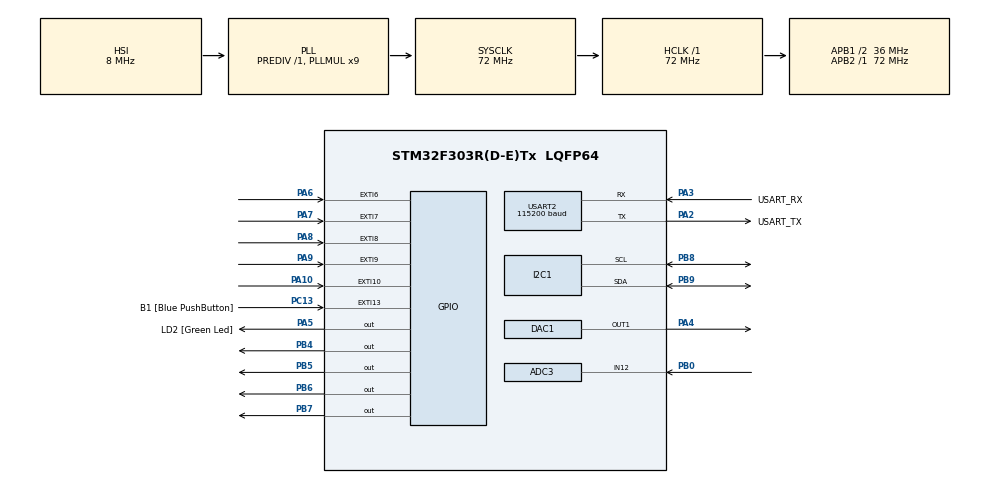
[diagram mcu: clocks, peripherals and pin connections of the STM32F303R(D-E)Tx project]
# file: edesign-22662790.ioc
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ADC1.Channel-2\#ChannelRegularConversion=ADC_CHANNEL_TEMPSENSOR
ADC1.NbrOfConversionFlag=1
ADC1.Offset-2\#ChannelRegularConversion=0
ADC1.OffsetNumber-2\#ChannelRegularConversion=ADC_OFFSET_NONE
ADC1.Rank-2\#ChannelRegularConversion=1
ADC1.SamplingTime-2\#ChannelRegularConversion=ADC_SAMPLETIME_1CYCLE_5
ADC1.master=1
ADC3.Channel-0\#ChannelRegularConversion=ADC_CHANNEL_12
ADC3.ContinuousConvMode=ENABLE
ADC3.DMAContinuousRequests=DISABLE
ADC3.NbrOfConversionFlag=1
ADC3.Offset-0\#ChannelRegularConversion=0
ADC3.OffsetNumber-0\#ChannelRegularConversion=ADC_OFFSET_NONE
ADC3.Rank-0\#ChannelRegularConversion=1
ADC3.SamplingTime-0\#ChannelRegularConversion=ADC_SAMPLETIME_2CYCLES_5
ADC3.master=1
Mcu.Family=STM32F3
Mcu.Name=STM32F303R(D-E)Tx
Mcu.Package=LQFP64
NVIC.ADC3_IRQn=true\:0\:0\:false\:false\:true\:true\:true
NVIC.EXTI15_10_IRQn=true\:0\:0\:false\:false\:true\:true\:true
NVIC.EXTI9_5_IRQn=true\:0\:0\:false\:false\:true\:true\:true
NVIC.PriorityGroup=NVIC_PRIORITYGROUP_0
NVIC.USART2_IRQn=true\:0\:0\:false\:false\:true\:true\:true
PA10.GPIO_ModeDefaultEXTI=GPIO_MODE_IT_RISING_FALLING
PA10.GPIO_PuPd=GPIO_PULLUP
PA10.Signal=GPXTI10
PA13.GPIO_Label=TMS
PA13.Mode=Serial_Wire
PA13.Signal=SYS_JTMS-SWDIO
PA14.GPIO_Label=TCK
PA14.Mode=Serial_Wire
PA14.Signal=SYS_JTCK-SWCLK
PA2.GPIO_Label=USART_TX
PA2.GPIO_Mode=GPIO_MODE_AF_PP
PA2.GPIO_PuPd=GPIO_NOPULL
PA2.GPIO_Speed=GPIO_SPEED_FREQ_LOW
PA2.Mode=Asynchronous
PA2.Signal=USART2_TX
PA3.GPIO_Label=USART_RX
PA3.GPIO_Mode=GPIO_MODE_AF_PP
PA3.GPIO_PuPd=GPIO_NOPULL
PA3.GPIO_Speed=GPIO_SPEED_FREQ_LOW
PA3.Mode=Asynchronous
PA3.Signal=USART2_RX
PA4.Signal=COMP_DAC11_group
PA5.GPIO_Label=LD2 [Green Led]
PA5.GPIO_Mode=GPIO_MODE_OUTPUT_PP
PA5.GPIO_PuPd=GPIO_NOPULL
PA5.GPIO_Speed=GPIO_SPEED_FREQ_LOW
PA5.Signal=GPIO_Output
PA6.GPIO_ModeDefaultEXTI=GPIO_MODE_IT_RISING_FALLING
PA6.GPIO_PuPd=GPIO_PULLUP
PA6.Signal=GPXTI6
PA7.GPIO_ModeDefaultEXTI=GPIO_MODE_IT_RISING_FALLING
PA7.GPIO_PuPd=GPIO_PULLUP
PA7.Signal=GPXTI7
PA8.GPIO_ModeDefaultEXTI=GPIO_MODE_IT_RISING_FALLING
PA8.GPIO_PuPd=GPIO_PULLUP
PA8.Signal=GPXTI8
PA9.GPIO_ModeDefaultEXTI=GPIO_MODE_IT_RISING_FALLING
PA9.GPIO_PuPd=GPIO_PULLUP
PA9.Signal=GPXTI9
PB0.Mode=IN12-Single-Ended
PB0.Signal=ADC3_IN12
PB3.GPIO_Label=SWO
PB3.Signal=SYS_JTDO-TRACESWO
PB4.Signal=GPIO_Output
PB5.Signal=GPIO_Output
PB6.Signal=GPIO_Output
PB7.Signal=GPIO_Output
PB8.Mode=I2C
PB8.Signal=I2C1_SCL
PB9.Mode=I2C
PB9.Signal=I2C1_SDA
PC13.GPIO_Label=B1 [Blue PushButton]
PC13.GPIO_ModeDefaultEXTI=GPIO_MODE_IT_FALLING
PC13.Signal=GPXTI13
PC14-OSC32_IN.Mode=LSE-External-Oscillator
PC14-OSC32_IN.Signal=RCC_OSC32_IN
PC15-OSC32_OUT.Mode=LSE-External-Oscillator
PC15-OSC32_OUT.Signal=RCC_OSC32_OUT
PF0-OSC_IN.Mode=HSE-External-Clock-Source
PF0-OSC_IN.Signal=RCC_OSC_IN
PF1-OSC_OUT.Signal=RCC_OSC_OUT
ProjectManager.HeapSize=0x200
ProjectManager.StackSize=0x400
ProjectManager.TargetToolchain=STM32CubeIDE
RCC.ADC34PRES=RCC_ADC34PLLCLK_DIV12
RCC.AHBFreq_Value=72000000
RCC.APB1CLKDivider=RCC_HCLK_DIV2
RCC.APB1Freq_Value=36000000
RCC.APB1TimFreq_Value=72000000
RCC.APB2Freq_Value=72000000
RCC.APB2TimFreq_Value=72000000
RCC.CortexFreq_Value=72000000
RCC.HCLKFreq_Value=72000000
RCC.HSE_VALUE=8000000
RCC.HSI_VALUE=8000000
RCC.PLLM=8
RCC.PLLMUL=RCC_PLL_MUL9
RCC.PLLN=336
RCC.PLLP=RCC_PLLP_DIV4
RCC.PLLQ=7
RCC.RCC_PLLsource_Clock_Source_FROM_HSE=RCC_HSE_PREDIV_DIV2
RCC.SYSCLKFreq_VALUE=72000000
RCC.SYSCLKSourceVirtual=RCC_SYSCLKSOURCE_PLLCLK
RCC.USBFreq_Value=72000000
SH.COMP_DAC11_group.0=DAC1_OUT1,DAC_OUT1
USART2.BaudRate=115200
USART2.VirtualMode-Asynchronous=VM_ASYNC
VP_ADC1_TempSens_Input.Mode=IN-TempSens
board=NUCLEO-F303RE

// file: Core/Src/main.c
/* USER CODE BEGIN Header */
/**
  ******************************************************************************
  * @file           : main.c
  * @brief          : Main program body
  ******************************************************************************
  * @attention
  *
  * <h2><center>&copy; Copyright (c) 2022 STMicroelectronics.
  * All rights reserved.</center></h2>
  *
  * This software component is licensed by ST under BSD 3-Clause license,
  * the "License"; You may not use this file except in compliance with the
  * License. You may obtain a copy of the License at:
  *                        opensource.org/licenses/BSD-3-Clause
  *
  ******************************************************************************
  */
/* USER CODE END Header */

#include "main.h"

/* USER CODE BEGIN Includes */
#include "multitool.h"
/* USER CODE END Includes */

ADC_HandleTypeDef hadc1;
ADC_HandleTypeDef hadc3;

DAC_HandleTypeDef hdac1;

I2C_HandleTypeDef hi2c1;

UART_HandleTypeDef huart2;

void SystemClock_Config(void);
static void MX_GPIO_Init(void);
static void MX_ADC1_Init(void);
static void MX_ADC3_Init(void);
static void MX_DAC1_Init(void);
static void MX_I2C1_Init(void);
static void MX_USART2_UART_Init(void);

int main(void)
{

  /* MCU Configuration--------------------------------------------------------*/

  /* Reset of all peripherals, Initializes the Flash interface and the Systick. */
  HAL_Init();

  /* USER CODE BEGIN Init */
  multitool_init();
  /* USER CODE END Init */

  /* Configure the system clock */
  SystemClock_Config();

  /* Initialize all configured peripherals */
  MX_GPIO_Init();
  MX_ADC1_Init();
  MX_ADC3_Init();
  MX_DAC1_Init();
  MX_I2C1_Init();
  MX_USART2_UART_Init();
  /* USER CODE BEGIN 2 */
  huartp = &huart2;
  hadcpt = &hadc1;
  hadcpv = &hadc3;
  multitool_startup();
  /* USER CODE END 2 */

  /* Infinite loop */
  while (1)
  {

    /* USER CODE BEGIN 3 */
	multitool_loop();
  }
  /* USER CODE END 3 */
}

void SystemClock_Config(void)
{
  RCC_OscInitTypeDef RCC_OscInitStruct = {0};
  RCC_ClkInitTypeDef RCC_ClkInitStruct = {0};
  RCC_PeriphCLKInitTypeDef PeriphClkInit = {0};

  /** Initializes the CPU, AHB and APB busses clocks
  */
  RCC_OscInitStruct.OscillatorType = RCC_OSCILLATORTYPE_HSI;
  RCC_OscInitStruct.HSIState = RCC_HSI_ON;
  RCC_OscInitStruct.HSICalibrationValue = RCC_HSICALIBRATION_DEFAULT;
  RCC_OscInitStruct.PLL.PLLState = RCC_PLL_ON;
  RCC_OscInitStruct.PLL.PLLSource = RCC_PLLSOURCE_HSI;
  RCC_OscInitStruct.PLL.PLLMUL = RCC_PLL_MUL9;
  RCC_OscInitStruct.PLL.PREDIV = RCC_PREDIV_DIV1;
  if (HAL_RCC_OscConfig(&RCC_OscInitStruct) != HAL_OK)
  {
    Error_Handler();
  }
  /** Initializes the CPU, AHB and APB busses clocks
  */
  RCC_ClkInitStruct.ClockType = RCC_CLOCKTYPE_HCLK|RCC_CLOCKTYPE_SYSCLK
                              |RCC_CLOCKTYPE_PCLK1|RCC_CLOCKTYPE_PCLK2;
  RCC_ClkInitStruct.SYSCLKSource = RCC_SYSCLKSOURCE_PLLCLK;
  RCC_ClkInitStruct.AHBCLKDivider = RCC_SYSCLK_DIV1;
  RCC_ClkInitStruct.APB1CLKDivider = RCC_HCLK_DIV2;
  RCC_ClkInitStruct.APB2CLKDivider = RCC_HCLK_DIV1;

  if (HAL_RCC_ClockConfig(&RCC_ClkInitStruct, FLASH_LATENCY_2) != HAL_OK)
  {
    Error_Handler();
  }
  PeriphClkInit.PeriphClockSelection = RCC_PERIPHCLK_USART2|RCC_PERIPHCLK_I2C1
                              |RCC_PERIPHCLK_ADC12|RCC_PERIPHCLK_ADC34;
  PeriphClkInit.Usart2ClockSelection = RCC_USART2CLKSOURCE_PCLK1;
  PeriphClkInit.Adc12ClockSelection = RCC_ADC12PLLCLK_DIV1;
  PeriphClkInit.Adc34ClockSelection = RCC_ADC34PLLCLK_DIV12;
  PeriphClkInit.I2c1ClockSelection = RCC_I2C1CLKSOURCE_HSI;
  if (HAL_RCCEx_PeriphCLKConfig(&PeriphClkInit) != HAL_OK)
  {
    Error_Handler();
  }
}

static void MX_ADC1_Init(void)
{

  ADC_MultiModeTypeDef multimode = {0};
  ADC_ChannelConfTypeDef sConfig = {0};

  /** Common config
  */
  hadc1.Instance = ADC1;
  hadc1.Init.ClockPrescaler = ADC_CLOCK_ASYNC_DIV1;
  hadc1.Init.Resolution = ADC_RESOLUTION_12B;
  hadc1.Init.ScanConvMode = ADC_SCAN_DISABLE;
  hadc1.Init.ContinuousConvMode = DISABLE;
  hadc1.Init.DiscontinuousConvMode = DISABLE;
  hadc1.Init.ExternalTrigConvEdge = ADC_EXTERNALTRIGCONVEDGE_NONE;
  hadc1.Init.ExternalTrigConv = ADC_SOFTWARE_START;
  hadc1.Init.DataAlign = ADC_DATAALIGN_RIGHT;
  hadc1.Init.NbrOfConversion = 1;
  hadc1.Init.DMAContinuousRequests = DISABLE;
  hadc1.Init.EOCSelection = ADC_EOC_SINGLE_CONV;
  hadc1.Init.LowPowerAutoWait = DISABLE;
  hadc1.Init.Overrun = ADC_OVR_DATA_OVERWRITTEN;
  if (HAL_ADC_Init(&hadc1) != HAL_OK)
  {
    Error_Handler();
  }
  /** Configure the ADC multi-mode
  */
  multimode.Mode = ADC_MODE_INDEPENDENT;
  if (HAL_ADCEx_MultiModeConfigChannel(&hadc1, &multimode) != HAL_OK)
  {
    Error_Handler();
  }
  /** Configure Regular Channel
  */
  sConfig.Channel = ADC_CHANNEL_TEMPSENSOR;
  sConfig.Rank = ADC_REGULAR_RANK_1;
  sConfig.SingleDiff = ADC_SINGLE_ENDED;
  sConfig.SamplingTime = ADC_SAMPLETIME_1CYCLE_5;
  sConfig.OffsetNumber = ADC_OFFSET_NONE;
  sConfig.Offset = 0;
  if (HAL_ADC_ConfigChannel(&hadc1, &sConfig) != HAL_OK)
  {
    Error_Handler();
  }

}

static void MX_ADC3_Init(void)
{

  ADC_MultiModeTypeDef multimode = {0};
  ADC_ChannelConfTypeDef sConfig = {0};

  /** Common config
  */
  hadc3.Instance = ADC3;
  hadc3.Init.ClockPrescaler = ADC_CLOCK_ASYNC_DIV1;
  hadc3.Init.Resolution = ADC_RESOLUTION_12B;
  hadc3.Init.ScanConvMode = ADC_SCAN_DISABLE;
  hadc3.Init.ContinuousConvMode = ENABLE;
  hadc3.Init.DiscontinuousConvMode = DISABLE;
  hadc3.Init.ExternalTrigConvEdge = ADC_EXTERNALTRIGCONVEDGE_NONE;
  hadc3.Init.ExternalTrigConv = ADC_SOFTWARE_START;
  hadc3.Init.DataAlign = ADC_DATAALIGN_RIGHT;
  hadc3.Init.NbrOfConversion = 1;
  hadc3.Init.DMAContinuousRequests = DISABLE;
  hadc3.Init.EOCSelection = ADC_EOC_SINGLE_CONV;
  hadc3.Init.LowPowerAutoWait = DISABLE;
  hadc3.Init.Overrun = ADC_OVR_DATA_OVERWRITTEN;
  if (HAL_ADC_Init(&hadc3) != HAL_OK)
  {
    Error_Handler();
  }
  /** Configure the ADC multi-mode
  */
  multimode.Mode = ADC_MODE_INDEPENDENT;
  if (HAL_ADCEx_MultiModeConfigChannel(&hadc3, &multimode) != HAL_OK)
  {
    Error_Handler();
  }
  /** Configure Regular Channel
  */
  sConfig.Channel = ADC_CHANNEL_12;
  sConfig.Rank = ADC_REGULAR_RANK_1;
  sConfig.SingleDiff = ADC_SINGLE_ENDED;
  sConfig.SamplingTime = ADC_SAMPLETIME_2CYCLES_5;
  sConfig.OffsetNumber = ADC_OFFSET_NONE;
  sConfig.Offset = 0;
  if (HAL_ADC_ConfigChannel(&hadc3, &sConfig) != HAL_OK)
  {
    Error_Handler();
  }

}

static void MX_DAC1_Init(void)
{

  DAC_ChannelConfTypeDef sConfig = {0};

  /** DAC Initialization
  */
  hdac1.Instance = DAC1;
  if (HAL_DAC_Init(&hdac1) != HAL_OK)
  {
    Error_Handler();
  }
  /** DAC channel OUT1 config
  */
  sConfig.DAC_Trigger = DAC_TRIGGER_NONE;
  sConfig.DAC_OutputBuffer = DAC_OUTPUTBUFFER_ENABLE;
  if (HAL_DAC_ConfigChannel(&hdac1, &sConfig, DAC_CHANNEL_1) != HAL_OK)
  {
    Error_Handler();
  }

}

static void MX_I2C1_Init(void)
{

  hi2c1.Instance = I2C1;
  hi2c1.Init.Timing = 0x2000090E;
  hi2c1.Init.OwnAddress1 = 0;
  hi2c1.Init.AddressingMode = I2C_ADDRESSINGMODE_7BIT;
  hi2c1.Init.DualAddressMode = I2C_DUALADDRESS_DISABLE;
  hi2c1.Init.OwnAddress2 = 0;
  hi2c1.Init.OwnAddress2Masks = I2C_OA2_NOMASK;
  hi2c1.Init.GeneralCallMode = I2C_GENERALCALL_DISABLE;
  hi2c1.Init.NoStretchMode = I2C_NOSTRETCH_DISABLE;
  if (HAL_I2C_Init(&hi2c1) != HAL_OK)
  {
    Error_Handler();
  }
  /** Configure Analogue filter
  */
  if (HAL_I2CEx_ConfigAnalogFilter(&hi2c1, I2C_ANALOGFILTER_ENABLE) != HAL_OK)
  {
    Error_Handler();
  }
  /** Configure Digital filter
  */
  if (HAL_I2CEx_ConfigDigitalFilter(&hi2c1, 0) != HAL_OK)
  {
    Error_Handler();
  }

}

static void MX_USART2_UART_Init(void)
{

  huart2.Instance = USART2;
  huart2.Init.BaudRate = 115200;
  huart2.Init.WordLength = UART_WORDLENGTH_8B;
  huart2.Init.StopBits = UART_STOPBITS_1;
  huart2.Init.Parity = UART_PARITY_NONE;
  huart2.Init.Mode = UART_MODE_TX_RX;
  huart2.Init.HwFlowCtl = UART_HWCONTROL_NONE;
  huart2.Init.OverSampling = UART_OVERSAMPLING_16;
  huart2.Init.OneBitSampling = UART_ONE_BIT_SAMPLE_DISABLE;
  huart2.AdvancedInit.AdvFeatureInit = UART_ADVFEATURE_NO_INIT;
  if (HAL_UART_Init(&huart2) != HAL_OK)
  {
    Error_Handler();
  }

}

static void MX_GPIO_Init(void)
{
  GPIO_InitTypeDef GPIO_InitStruct = {0};

  /* GPIO Ports Clock Enable */
  __HAL_RCC_GPIOC_CLK_ENABLE();
  __HAL_RCC_GPIOF_CLK_ENABLE();
  __HAL_RCC_GPIOA_CLK_ENABLE();
  __HAL_RCC_GPIOB_CLK_ENABLE();

  /*Configure GPIO pin Output Level */
  HAL_GPIO_WritePin(LD2_GPIO_Port, LD2_Pin, GPIO_PIN_RESET);

  /*Configure GPIO pin Output Level */
  HAL_GPIO_WritePin(GPIOB, GPIO_PIN_4|GPIO_PIN_5|GPIO_PIN_6|GPIO_PIN_7, GPIO_PIN_RESET);

  /*Configure GPIO pin : B1_Pin */
  GPIO_InitStruct.Pin = B1_Pin;
  GPIO_InitStruct.Mode = GPIO_MODE_IT_FALLING;
  GPIO_InitStruct.Pull = GPIO_NOPULL;
  HAL_GPIO_Init(B1_GPIO_Port, &GPIO_InitStruct);

  /*Configure GPIO pin : LD2_Pin */
  GPIO_InitStruct.Pin = LD2_Pin;
  GPIO_InitStruct.Mode = GPIO_MODE_OUTPUT_PP;
  GPIO_InitStruct.Pull = GPIO_NOPULL;
  GPIO_InitStruct.Speed = GPIO_SPEED_FREQ_LOW;
  HAL_GPIO_Init(LD2_GPIO_Port, &GPIO_InitStruct);

  /*Configure GPIO pins : PA6 PA7 PA8 PA9
                           PA10 */
  GPIO_InitStruct.Pin = GPIO_PIN_6|GPIO_PIN_7|GPIO_PIN_8|GPIO_PIN_9
                          |GPIO_PIN_10;
  GPIO_InitStruct.Mode = GPIO_MODE_IT_RISING_FALLING;
  GPIO_InitStruct.Pull = GPIO_PULLUP;
  HAL_GPIO_Init(GPIOA, &GPIO_InitStruct);

  /*Configure GPIO pins : PB4 PB5 PB6 PB7 */
  GPIO_InitStruct.Pin = GPIO_PIN_4|GPIO_PIN_5|GPIO_PIN_6|GPIO_PIN_7;
  GPIO_InitStruct.Mode = GPIO_MODE_OUTPUT_PP;
  GPIO_InitStruct.Pull = GPIO_NOPULL;
  GPIO_InitStruct.Speed = GPIO_SPEED_FREQ_LOW;
  HAL_GPIO_Init(GPIOB, &GPIO_InitStruct);

  /* EXTI interrupt init*/
  HAL_NVIC_SetPriority(EXTI9_5_IRQn, 0, 0);
  HAL_NVIC_EnableIRQ(EXTI9_5_IRQn);

  HAL_NVIC_SetPriority(EXTI15_10_IRQn, 0, 0);
  HAL_NVIC_EnableIRQ(EXTI15_10_IRQn);

}

void Error_Handler(void)
{
}

/************************ (C) COPYRIGHT STMicroelectronics *****END OF FILE****/
